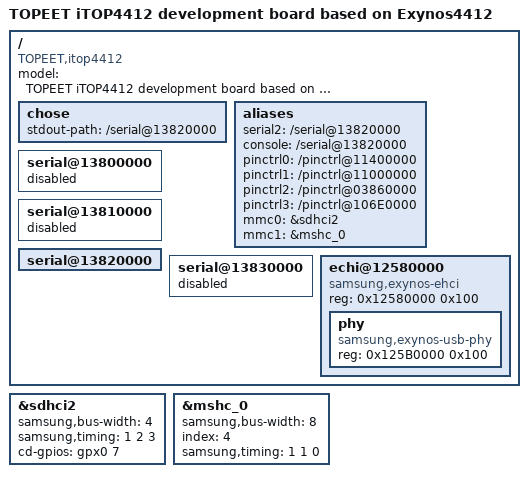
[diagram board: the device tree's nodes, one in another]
// SPDX-License-Identifier: GPL-2.0+
/*
 * Refer to exynos4210-origen.dts
 *
 * TOPEET iTOP4412 development board(based on Exynos4412 SoC) device tree
 * source
 *
 * Copyright (C) 2019   Wang Xinlu <wangkartx@gmail.com>
 *
 */

/dts-v1/;
#include "exynos4412.dtsi"

/ {
	model = "TOPEET iTOP4412 development board based on Exynos4412";
	compatible = "TOPEET,itop4412", "samsung,exynos4412";

	chose {
		stdout-path = "/serial@13820000";
	};

	aliases {
		serial2 = "/serial@13820000";
		console = "/serial@13820000";
		pinctrl0 = "/pinctrl@11400000";
		pinctrl1 = "/pinctrl@11000000";
		pinctrl2 = "/pinctrl@03860000";
		pinctrl3 = "/pinctrl@106E0000";
		mmc0 = &sdhci2;
		mmc1 = &mshc_0;
	};

	serial@13800000 {
		status = "disabled";
	};

	serial@13810000 {
		status = "disabled";
	};

	serial@13820000 {
		status = "okay";
	};

	serial@13830000 {
		status = "disabled";
	};
        
	echi@12580000 {
		compatible = "samsung,exynos-ehci";
		reg = <0x12580000 0x100>;
		#address-cells = <1>;
		#size-cells = <1>;
		phy {
			compatible = "samsung,exynos-usb-phy";
			reg = <0x125B0000 0x100>;
		};
        };
};

&sdhci2 {
	samsung,bus-width = <4>;
	samsung,timing = <1 2 3>;
	cd-gpios = <&gpx0 7 0>;
	status = "okay";
};

&mshc_0 {
	samsung,bus-width = <8>;
	index = <4>;
	samsung,timing = <1 1 0>;
	status = "okay";
};
